# GD32E232 register map
File version: 1.0
CPU: CM23 r0p0, little endian, MPU, FPU, 4 interrupt priority bits
Registers are 32-bit, read-write, reset 0x0 unless marked. A register's access mark holds for its fields unless they carry their own. Offsets are from the block's base; [hi:lo] are bit positions; {n}, {i} and the like mark numbered series.

## SYSCFG — System configuration controller
Base 0x40010000
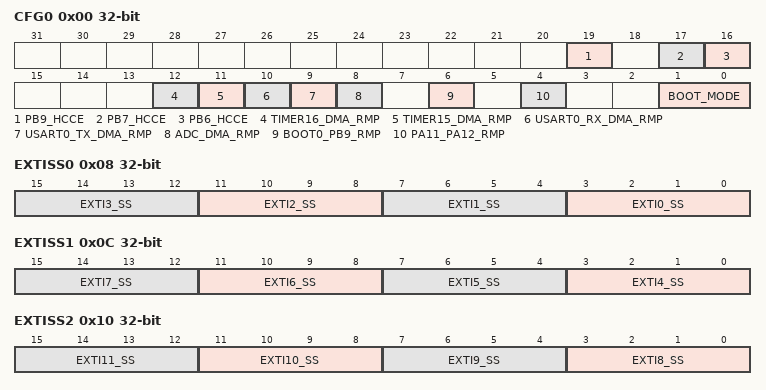
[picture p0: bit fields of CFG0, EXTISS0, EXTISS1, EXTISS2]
0x00 CFG0 — System configuration register 0
  [19] PB9_HCCE — PB9 pin high current capability enable
  [17] PB7_HCCE — PB7 pin high current capability enable
  [16] PB6_HCCE — PB6 pin high current capability enable
  [12] TIMER16_DMA_RMP — Timer 16 DMA request remapping enable
  [11] TIMER15_DMA_RMP — Timer 15 DMA request remapping enable
  [10] USART0_RX_DMA_RMP — USART0_RX DMA request remapping enable
  [9] USART0_TX_DMA_RMP — USART0_TX DMA request remapping enable
  [8] ADC_DMA_RMP — ADC DMA request remapping enable
  [6] BOOT0_PB9_RMP — BOOT0 and PB9 remapping bit
  [4] PA11_PA12_RMP — PA11 and PA12 remapping bit for small packages
  [1:0] BOOT_MODE ro
0x08 EXTISS0 — EXTI sources selection register 0
  [4n+3:4n] EXTI{n}_SS (n=0..3) — EXTI {n} sources selection
0x0C EXTISS1 — EXTI sources selection register 1
  [4n-13:4n-16] EXTI{n}_SS (n=4..7) — EXTI {n} sources selection
0x10 EXTISS2 — EXTI sources selection register 2
  [4n-29:4n-32] EXTI{n}_SS (n=8..11) — EXTI {n} sources selection
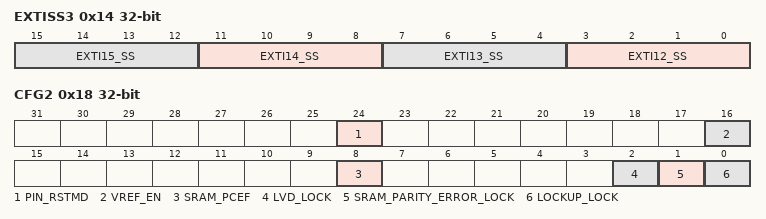
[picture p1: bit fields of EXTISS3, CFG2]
0x14 EXTISS3 — EXTI sources selection register 3
  [4n-45:4n-48] EXTI{n}_SS (n=12..15) — EXTI {n} sources selection
0x18 CFG2 — System configuration register 2
  [24] PIN_RSTMD — Pin reset mode
  [16] VREF_EN — VREF enable
  [8] SRAM_PCEF — SRAM parity check error flag
  [2] LVD_LOCK
  [1] SRAM_PARITY_ERROR_LOCK — SRAM parity check error lock
  [0] LOCKUP_LOCK — Cortex-M4 LOCKUP output lock
0x100 CPU_IRQ_LAT — IRQ Latency register
  [7:0] IRQ_LATENCY — specifies the minimum number of cycles between an interrupt

## TIMER5 — Basic-timers
Base 0x40001000
Same registers: TIMER6 0x40001400
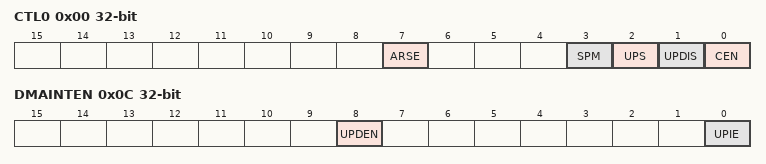
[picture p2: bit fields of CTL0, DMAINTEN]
0x00 CTL0 — control register 0
  [7] ARSE — Auto-reload preload enable
  [3] SPM — One-pulse mode
  [2] UPS — Update request source
  [1] UPDIS — Update disable
  [0] CEN — Counter enable
0x04 CTL1 — control register 1
  [6:4] MMC — Master mode selection
0x0C DMAINTEN — DMA/Interrupt enable register
  [8] UPDEN — Update DMA request enable
  [0] UPIE — Update interrupt enable
0x10 INTF — status register
  [0] UPIF — Update interrupt flag
0x14 SWEVG wo — event generation register
  [0] UPG — Update generation
0x24 CNT — counter
  [15:0] CNT — Low counter value
0x28 PSC — prescaler
  [15:0] PSC — Prescaler value
0x2C CAR — auto-reload register
  [15:0] CARL — Low Auto-reload value

## TIMER13 — General-purpose-timers
Base 0x40002000
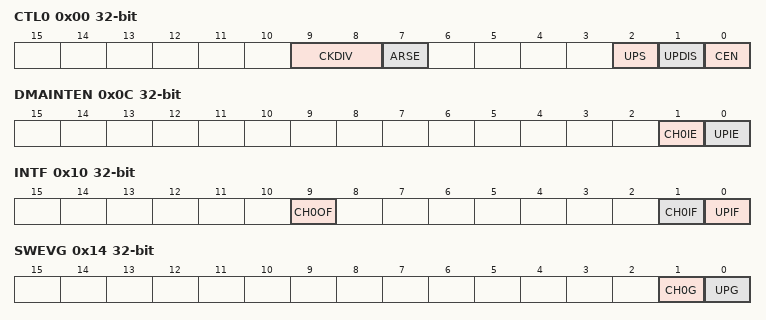
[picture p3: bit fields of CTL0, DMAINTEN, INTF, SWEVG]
0x00 CTL0 — control register 1
  [9:8] CKDIV — Clock division
  [7] ARSE — Auto-reload preload enable
  [2] UPS — Update request source
  [1] UPDIS — Update disable
  [0] CEN — Counter enable
0x0C DMAINTEN — DMA/Interrupt enable register
  [1] CH0IE — Capture/Compare 0 interrupt enable
  [0] UPIE — Update interrupt enable
0x10 INTF — interrupt flag register
  [9] CH0OF — Capture/Compare 0 overcapture flag
  [1] CH0IF — Capture/compare 0 interrupt flag
  [0] UPIF — Update interrupt flag
0x14 SWEVG wo — event generation register
  [1] CH0G — Capture/compare 0 generation
  [0] UPG — Update generation
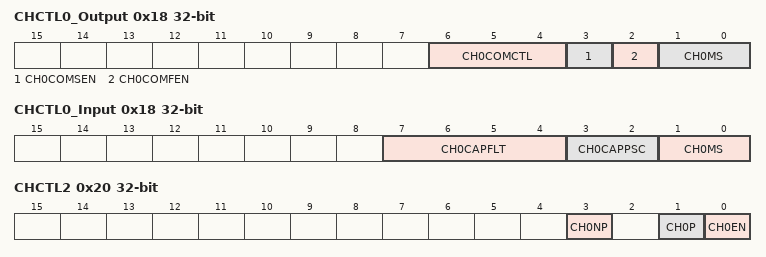
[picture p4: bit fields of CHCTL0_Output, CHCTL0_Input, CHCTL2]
0x18 CHCTL0_Output — capture/compare mode register (output mode)
  [6:4] CH0COMCTL — Output Compare 0 mode
  [3] CH0COMSEN — Output Compare 0 preload enable
  [2] CH0COMFEN — Output compare 0 fast enable
  [1:0] CH0MS — Capture/Compare 0 selection
0x18 CHCTL0_Input (alternate view of CHCTL0_Output) — capture/compare mode register (input mode)
  [7:4] CH0CAPFLT — Input capture 0 filter
  [3:2] CH0CAPPSC — Input capture 0 prescaler
  [1:0] CH0MS — Capture/Compare 0 selection
0x20 CHCTL2 — capture/compare enable register
  [3] CH0NP — Capture/Compare 0 output Polarity
  [1] CH0P — Capture/Compare 0 output Polarity
  [0] CH0EN — Capture/Compare 1 output enable
0x24 CNT — counter
  [15:0] CNT — counter value
0x28 PSC — prescaler
  [15:0] PSC — Prescaler value
0x2C CAR — auto-reload register
  [15:0] CARL — Auto-reload value
0x34 CH0CV — capture/compare register 0
  [15:0] CH0VAL — Capture/Compare 1 value
0x50 IRMP — channel input remap register
  [1:0] CI0_RMP — Timer input 0 remap
0xFC CFG — configuration register
  [1] CHVSEL — Write CHxVAL register selection

## TIMER15 — General-purpose-timers
Base 0x40014400
Same registers: TIMER16 0x40014800
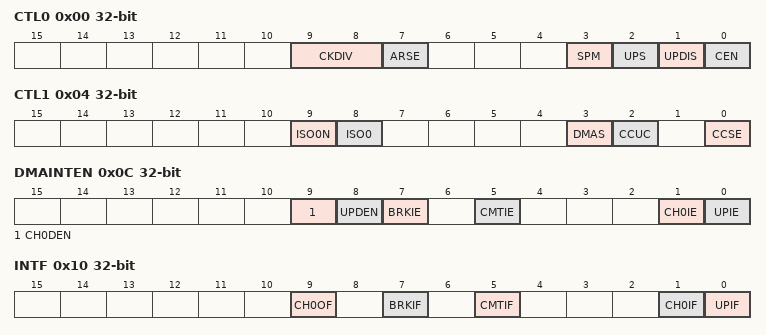
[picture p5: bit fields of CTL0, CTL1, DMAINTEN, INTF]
0x00 CTL0 — control register 0
  [9:8] CKDIV — Clock division
  [7] ARSE — Auto-reload preload enable
  [3] SPM — One-pulse mode
  [2] UPS — Update request source
  [1] UPDIS — Update disable
  [0] CEN — Counter enable
0x04 CTL1 — control register 1
  [9] ISO0N — Output Idle state 0
  [8] ISO0 — Output Idle state 0
  [3] DMAS — Capture/compare DMA selection
  [2] CCUC — Capture/compare control update selection
  [0] CCSE — Capture/compare preloaded control
0x0C DMAINTEN — DMA/Interrupt enable register
  [9] CH0DEN — Capture/Compare 0 DMA request enable
  [8] UPDEN — Update DMA request enable
  [7] BRKIE — Break interrupt enable
  [5] CMTIE — COM interrupt enable
  [1] CH0IE — Capture/Compare 0 interrupt enable
  [0] UPIE — Update interrupt enable
0x10 INTF — interrupt flag register
  [9] CH0OF — Capture/Compare 0 overcapture flag
  [7] BRKIF — Break interrupt flag
  [5] CMTIF — COM interrupt flag
  [1] CH0IF — Capture/compare 0 interrupt flag
  [0] UPIF — Update interrupt flag
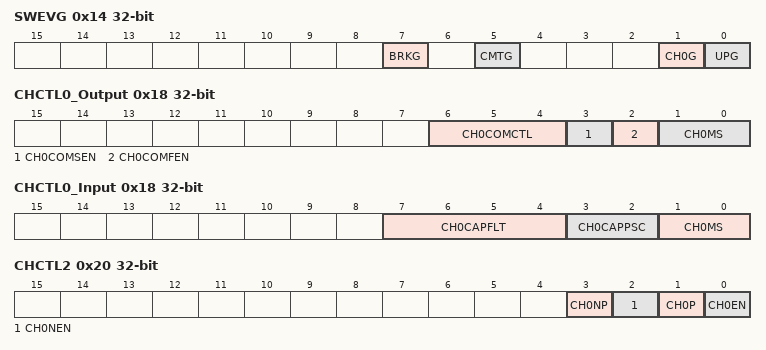
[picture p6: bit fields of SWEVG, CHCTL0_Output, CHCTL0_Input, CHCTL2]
0x14 SWEVG wo — event generation register
  [7] BRKG — Break generation
  [5] CMTG — Capture/Compare control update generation
  [1] CH0G — Capture/compare 0 generation
  [0] UPG — Update generation
0x18 CHCTL0_Output — capture/compare mode register (output mode)
  [6:4] CH0COMCTL — Output Compare 0 mode
  [3] CH0COMSEN — Output Compare 0 preload enable
  [2] CH0COMFEN — Output Compare 0 fast enable
  [1:0] CH0MS — Capture/Compare 0 selection
0x18 CHCTL0_Input (alternate view of CHCTL0_Output) — capture/compare mode register 0 (input mode)
  [7:4] CH0CAPFLT — Input capture 0 filter
  [3:2] CH0CAPPSC — Input capture 0 prescaler
  [1:0] CH0MS — Capture/Compare 0 selection
0x20 CHCTL2 — capture/compare enable register
  [3] CH0NP — Capture/Compare 0 output Polarity
  [2] CH0NEN — Capture/Compare 0 complementary output enable
  [1] CH0P — Capture/Compare 0 output Polarity
  [0] CH0EN — Capture/Compare 0 output enable
0x24 CNT — counter
  [15:0] CNT — counter value
0x28 PSC — prescaler
  [15:0] PSC — Prescaler value
0x2C CAR — auto-reload register
  [15:0] CARL — Auto-reload value
0x30 CREP — repetition counter register
  [7:0] CREP — Repetition counter value
0x34 CH0CV — capture/compare register 0
  [15:0] CH0VAL — Capture/Compare 0 value
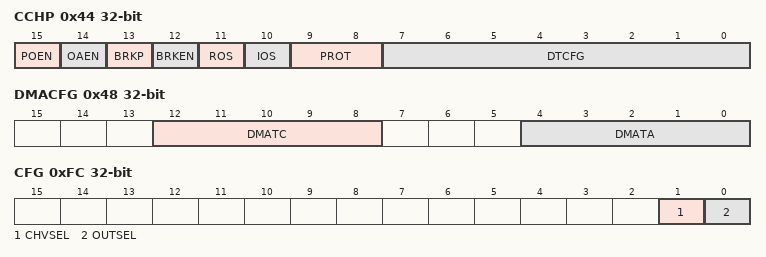
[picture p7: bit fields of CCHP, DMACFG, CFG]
0x44 CCHP — break and dead-time register
  [15] POEN — Main output enable
  [14] OAEN — Automatic output enable
  [13] BRKP — Break polarity
  [12] BRKEN — Break enable
  [11] ROS — Off-state selection for Run mode
  [10] IOS — Off-state selection for Idle mode
  [9:8] PROT — complementary register protect control
  [7:0] DTCFG — Dead-time generator setup
0x48 DMACFG — DMA configuration register
  [12:8] DMATC — DMA transfer count
  [4:0] DMATA — DMA transfer access start address
0x4C DMATB — DMA transfer buffer register
  [15:0] DMATB — DMA register for burst accesses
0xFC CFG — configuration register
  [1] CHVSEL — Write CHxVAL register selection
  [0] OUTSEL — The output value selection

## WWDGT — Window watchdog timer
Base 0x40002C00
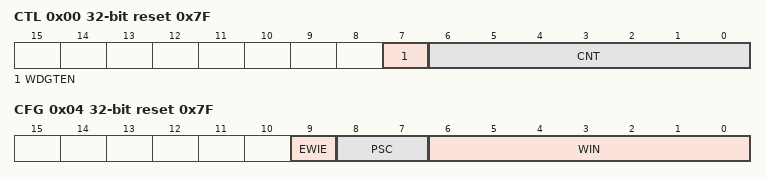
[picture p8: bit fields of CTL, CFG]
0x00 CTL reset 0x7F — Control register
  [7] WDGTEN — Activation bit
  [6:0] CNT — 7-bit counter
0x04 CFG reset 0x7F — Configuration register
  [9] EWIE — Early wakeup interrupt
  [8:7] PSC — Prescaler
  [6:0] WIN — 7-bit window value
0x08 STAT — Status register
  [0] EWIF — Early wakeup interrupt flag
